# MSP430F5529 register map
Vendor: msp430gen; File version: VERGEN_IDEMPOTENT_OUTPUT
Registers are 8-bit, read-write, reset 0x0 unless marked. A register's access mark holds for its fields unless they carry their own. Offsets are from the block's base; [hi:lo] are bit positions; {n}, {i} and the like mark numbered series.

## COMPARATOR_B
Base 0x000008C0
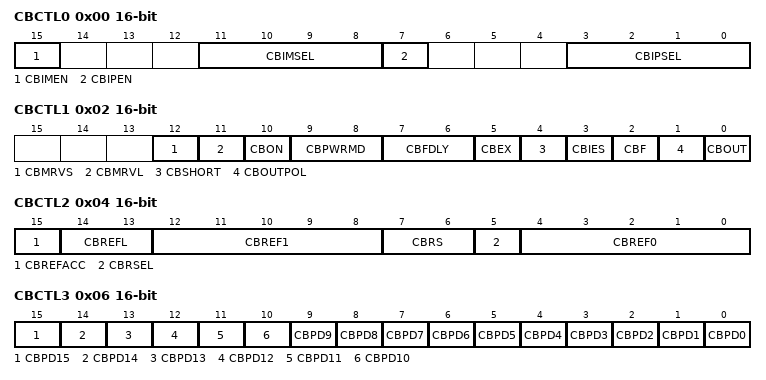
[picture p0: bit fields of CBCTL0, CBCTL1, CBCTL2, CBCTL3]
0x00 CBCTL0 16-bit — Comparator B Control Register 0
  [15] CBIMEN — Comp. B Neg. Channel Input Enable
  [11:8] CBIMSEL — Comp. B Neg. Channel Input Select 0
    {v}=Comp. B V- Terminal Input Select: Channel {v} (v=0..7); {v}=Comp. B V- terminal Input Select: Channel {v} (v=8..15)
  [7] CBIPEN — Comp. B Pos. Channel Input Enable
  [3:0] CBIPSEL — Comp. B Pos. Channel Input Select 0
    {v}=Comp. B V+ terminal Input Select: Channel {v} (v=0..15)
0x02 CBCTL1 16-bit — Comparator B Control Register 1
  [12] CBMRVS — Comp. B Output selects between VREF0 or VREF1
  [11] CBMRVL — Comp. B CBMRV Level
  [10] CBON — Comp. B enable
  [9:8] CBPWRMD — Comp. B Power Mode Bit 0
    0=Comp. B Power Mode 0 : High speed; 1=Comp. B Power Mode 1 : Normal; 2=Comp. B Power Mode 2 : Ultra-Low; 3=Comp. B Power Mode 3 : Reserved
  [7:6] CBFDLY — Comp. B Filter delay Bit 0
    0=Comp. B Filter delay 0 : 450ns; 1=Comp. B Filter delay 1 : 900ns; 2=Comp. B Filter delay 2 : 1800ns; 3=Comp. B Filter delay 3 : 3600ns
  [5] CBEX — Comp. B Exchange Inputs
  [4] CBSHORT — Comp. B Input Short
  [3] CBIES — Comp. B Interrupt Edge Select
  [2] CBF — Comp. B Enable Output Filter
  [1] CBOUTPOL — Comp. B Output Polarity
  [0] CBOUT — Comp. B Output
0x04 CBCTL2 16-bit — Comparator B Control Register 2
  [15] CBREFACC — Comp. B Reference Accuracy
  [14:13] CBREFL — Comp. B Reference voltage level Bit : 0
    0=Comp. B Reference voltage level 0 : None; 1=Comp. B Reference voltage level 1 : 1.5V; 2=Comp. B Reference voltage level 2 : 2.0V; 3=Comp. B Reference voltage level 3 : 2.5V
  [12:8] CBREF1 — Comp. B Reference 1 Resistor Select Bit : 0
    {v}=Comp. B Int. Ref.1 Select {v} : {v+1}/32 (v=0..7); {v}=Comp. B Int. Ref.1 Select {v-8} : {v+1}/32 (v=8..15); {v}=Comp. B Int. Ref.1 Select {v-16} : {v+1}/32 (v=16..23); {v}=Comp. B Int. Ref.1 Select {v-24} : {v+1}/32 (v=24..31)
  [7:6] CBRS — Comp. B Reference Source Bit : 0
    0=Comp. B Reference Source 0 : Off; 1=Comp. B Reference Source 1 : Vcc; 2=Comp. B Reference Source 2 : Shared Ref.; 3=Comp. B Reference Source 3 : Shared Ref. / Off
  [5] CBRSEL — Comp. B Reference select
  [4:0] CBREF0 — Comp. B Reference 0 Resistor Select Bit : 0
    {v}=Comp. B Int. Ref.0 Select {v} : {v+1}/32 (v=0..7); {v}=Comp. B Int. Ref.0 Select {v-8} : {v+1}/32 (v=8..15); {v}=Comp. B Int. Ref.0 Select {v-16} : {v+1}/32 (v=16..23); {v}=Comp. B Int. Ref.0 Select {v-24} : {v+1}/32 (v=24..31)
0x06 CBCTL3 16-bit — Comparator B Control Register 3
  [15] CBPD15 — Comp. B Disable Input Buffer of Port Register .15
  [14] CBPD14 — Comp. B Disable Input Buffer of Port Register .14
  [13] CBPD13 — Comp. B Disable Input Buffer of Port Register .13
  [12] CBPD12 — Comp. B Disable Input Buffer of Port Register .12
  [11] CBPD11 — Comp. B Disable Input Buffer of Port Register .11
  [10] CBPD10 — Comp. B Disable Input Buffer of Port Register .10
  [9] CBPD9 — Comp. B Disable Input Buffer of Port Register .9
  [8] CBPD8 — Comp. B Disable Input Buffer of Port Register .8
  [7] CBPD7 — Comp. B Disable Input Buffer of Port Register .7
  [6] CBPD6 — Comp. B Disable Input Buffer of Port Register .6
  [5] CBPD5 — Comp. B Disable Input Buffer of Port Register .5
  [4] CBPD4 — Comp. B Disable Input Buffer of Port Register .4
  [3] CBPD3 — Comp. B Disable Input Buffer of Port Register .3
  [2] CBPD2 — Comp. B Disable Input Buffer of Port Register .2
  [1] CBPD1 — Comp. B Disable Input Buffer of Port Register .1
  [0] CBPD0 — Comp. B Disable Input Buffer of Port Register .0
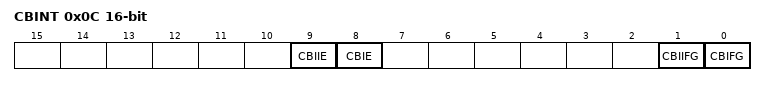
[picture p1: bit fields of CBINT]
0x0C CBINT 16-bit — Comparator B Interrupt Register
  [9] CBIIE — Comp. B Interrupt Enable Inverted Polarity
  [8] CBIE — Comp. B Interrupt Enable
  [1] CBIIFG — Comp. B Interrupt Flag Inverted Polarity
  [0] CBIFG — Comp. B Interrupt Flag
0x0E CBIV 16-bit — Comparator B Interrupt Vector Word
